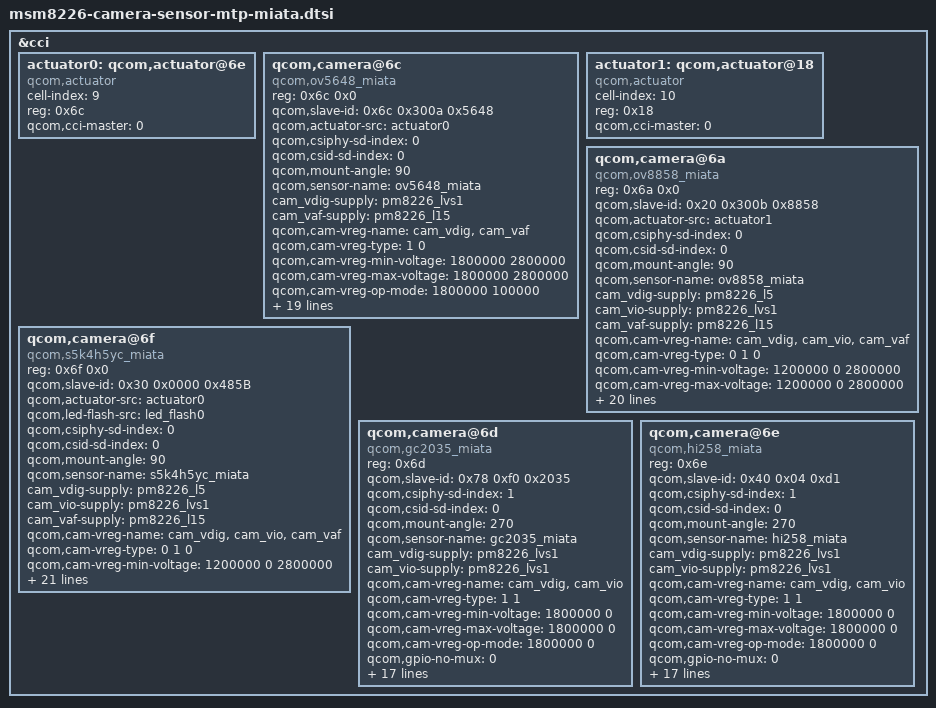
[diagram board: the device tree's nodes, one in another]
/*
 * Copyright (c) 2013, The Linux Foundation. All rights reserved.
 *
 * This program is free software; you can redistribute it and/or modify
 * it under the terms of the GNU General Public License version 2 and
 * only version 2 as published by the Free Software Foundation.
 *
 * This program is distributed in the hope that it will be useful,
 * but WITHOUT ANY WARRANTY; without even the implied warranty of
 * MERCHANTABILITY or FITNESS FOR A PARTICULAR PURPOSE.  See the
 * GNU General Public License for more details.
 *         Modify History For This Module
 * When           Who             What,Where,Why
 * --------------------------------------------------------------------------------------
 * 13/08/22      Hu Jin       Add driver for RoilTF's 1st main CAM
 * 13/10/22      Wang Penglei       Add driver for MIATA's 1st sub CAM GC2035
 * 13/10/25      Hu Jin       Add driver for MIATA's 1st main CAM ov5648
 * 13/10/29      Hu Jin       optimize
 * 13/11/26      Hu Jin       miata all main CAM -> 8M
 * 13/11/27      Hu Jin       fix 5M&8M issue
 * 13/12/11      Hu Jin       for i2c compatibility
 * 14/01/09      Hu Jin       Delete the old i2c
 * 14/01/19      Hu Jin       Camera can not be found on production
 * --------------------------------------------------------------------------------------
 */
// remove by shicuiping for we have not a camera flash start
/*&soc {

	led_flash0: qcom,camera-led-flash {
		cell-index = <0>;
		compatible = "qcom,camera-led-flash";
		qcom,flash-type = <1>;
		qcom,flash-source = <&pm8226_flash0 &pm8226_flash1>;
		qcom,torch-source = <&pm8226_torch>;
	};
};*/
// remove by shicuiping for we have not a camera flash stop

&cci {

	actuator0: qcom,actuator@6e {
		cell-index = <9>;/* [PLATFORM]-Mod by TCTNB.HJ, 2013/10/25*/
		reg = <0x6c>;
		compatible = "qcom,actuator";
		qcom,cci-master = <0>;
	};
/* [PLATFORM]-Mod-BEGIN by TCTNB.HJ, 2013/10/25*/
/*
	qcom,camera@6f {
		compatible = "qcom,ov8825";
		reg = <0x6f>;
		qcom,slave-id = <0x6c 0x300a 0x8825>;
		qcom,csiphy-sd-index = <0>;
		qcom,csid-sd-index = <0>;
		qcom,actuator-src = <&actuator0>;
		//qcom,led-flash-src = <&led_flash0>; // remove by shicuiping for we have not a camera flash
		qcom,mount-angle = <270>;
		qcom,sensor-name = "ov8825";
		cam_vdig-supply = <&pm8226_l5>;
		cam_vana-supply = <&pm8226_l19>;
		cam_vio-supply = <&pm8226_lvs1>;
		cam_vaf-supply = <&pm8226_l15>;
		qcom,cam-vreg-name = "cam_vdig", "cam_vio", "cam_vana",
							 "cam_vaf";
		qcom,cam-vreg-type = <0 1 0 0>;
		qcom,cam-vreg-min-voltage = <1200000 0 2850000 2800000>;
		qcom,cam-vreg-max-voltage = <1200000 0 2850000 2800000>;
		qcom,cam-vreg-op-mode = <200000 0 80000 100000>;
		qcom,gpio-no-mux = <0>;
		gpios = <&msmgpio 26 0>,
			<&msmgpio 37 0>,
			<&msmgpio 35 0>;
		qcom,gpio-reset = <1>;
		qcom,gpio-standby = <2>;
		qcom,gpio-req-tbl-num = <0 1 2>;
		qcom,gpio-req-tbl-flags = <1 0 0>;
		qcom,gpio-req-tbl-label = "CAMIF_MCLK",
			"CAM_RESET1",
			"CAM_STANDBY";
		qcom,csi-lane-assign = <0x4320>;
		qcom,csi-lane-mask = <0x1f>;
		qcom,sensor-position = <0>;
		qcom,sensor-mode = <1>;
		qcom,cci-master = <0>;
	};

	qcom,camera@6d {
		compatible = "qcom,ov9724";
		reg = <0x6d>;
		qcom,slave-id = <0x20 0x0 0x9724>;
		qcom,csiphy-sd-index = <1>;
		qcom,csid-sd-index = <1>;
		qcom,mount-angle = <270>;
		qcom,sensor-name = "ov9724";
		cam_vdig-supply = <&pm8226_l5>;
		cam_vana-supply = <&pm8226_l19>;
		cam_vio-supply = <&pm8226_lvs1>;
		qcom,cam-vreg-name = "cam_vdig", "cam_vio", "cam_vana";
		qcom,cam-vreg-type = <0 1 0>;
		qcom,cam-vreg-min-voltage = <1200000 0 2850000>;
		qcom,cam-vreg-max-voltage = <1200000 0 2850000>;
		qcom,cam-vreg-op-mode = <200000 0 80000>;
		qcom,gpio-no-mux = <0>;
		gpios = <&msmgpio 26 0>,
				<&msmgpio 28 0>,
				<&msmgpio 36 0>;
		qcom,gpio-reset = <1>;
		qcom,gpio-standby = <2>;
		qcom,gpio-req-tbl-num = <0 1 2>;
		qcom,gpio-req-tbl-flags = <1 0 0>;
		qcom,gpio-req-tbl-label = "CAMIF_MCLK",
				"CAM_RESET",
				"CAM_STANDBY";
		qcom,gpio-set-tbl-num = <1 1>;
		qcom,gpio-set-tbl-flags = <0 2>;
		qcom,gpio-set-tbl-delay = <1000 4000>;
		qcom,csi-lane-assign = <0x4320>;
		qcom,csi-lane-mask = <0x3>;
		qcom,sensor-position = <1>;
		qcom,sensor-mode = <1>;
		qcom,cci-master = <0>;
		status = "ok";
	};
*/
/* [PLATFORM]-Mod-END by TCTNB.HJ, 2013/10/25*/
/* [PLATFORM]-Mod-BEGIN by TCTNB.HJ, 2013/08/22, 1st main CAM dev (5M)*/
	qcom,camera@6c {
		compatible = "qcom,ov5648_miata";
		reg = <0x6c 0x0>;
		qcom,slave-id = <0x6c 0x300a 0x5648>;
		qcom,actuator-src = <&actuator0>;
		//qcom,led-flash-src = <&led_flash0>; // remove by shicuiping for we have not a camera flash
		qcom,csiphy-sd-index = <0>;
		qcom,csid-sd-index = <0>;
		qcom,mount-angle = <90>;
		qcom,sensor-name = "ov5648_miata";
		cam_vdig-supply = <&pm8226_lvs1>;
		cam_vaf-supply = <&pm8226_l15>;
		qcom,cam-vreg-name = "cam_vdig", "cam_vaf";
		qcom,cam-vreg-type = <1 0>;
		qcom,cam-vreg-min-voltage = <1800000 2800000>;
		qcom,cam-vreg-max-voltage = <1800000 2800000>;
		qcom,cam-vreg-op-mode = <1800000 100000>;
		qcom,gpio-no-mux = <0>;
		gpios = <&msmgpio 26 0>,
				<&msmgpio 37 0>,
				<&msmgpio 36 0>,
				<&msmgpio 31 0>,
				<&msmgpio 23 0>;
		qcom,gpio-reset = <1>;
		qcom,gpio-standby = <2>;
	       qcom,gpio-vana = <3>;
	       qcom,gpio-af-pwdm = <4>;
		qcom,gpio-req-tbl-num = <0 1 2 3 4>;
		qcom,gpio-req-tbl-flags = <1 0 0 0 0>;
		qcom,gpio-req-tbl-label = "CAMIF_MCLK",
				"CAM_RESET",
				"CAM_STANDBY",
				"CAM_VANA",
				"CAM_AF_PWDM";
		qcom,gpio-set-tbl-flags = <0 2>;
		qcom,gpio-set-tbl-delay = <1000 4000>;
		qcom,csi-lane-assign = <0x4320>;
		qcom,csi-lane-mask = <0x3>;
		qcom,sensor-position = <0>;
		qcom,sensor-mode = <0>;
		qcom,cci-master = <0>;
	};
/* [PLATFORM]-Mod-END by TCTNB.HJ, 2013/08/22 */

/* [PLATFORM]-Mod-BEGIN by TCTNB.HJ, 2013/11/26, 1st main CAM dev (8M)*/
	actuator1: qcom,actuator@18 {
		cell-index = <10>;
		reg = <0x18>;
		compatible = "qcom,actuator";
		qcom,cci-master = <0>;
	};
/* [PLATFORM]-Add-BEGIN by TCTNB.WPL, 2013/12/26, 2nd main CAM dev, refer to bug569849*/
    qcom,camera@6a {
        compatible = "qcom,ov8858_miata";
        reg = <0x6a 0x0>;
        qcom,slave-id = <0x20 0x300b 0x8858>;
        qcom,actuator-src = <&actuator1>;
        //qcom,led-flash-src = <&led_flash0>; // remove by shicuiping for we have not a camera flash
        qcom,csiphy-sd-index = <0>;
        qcom,csid-sd-index = <0>;
        qcom,mount-angle = <90>;
        qcom,sensor-name = "ov8858_miata";
        cam_vdig-supply = <&pm8226_l5>;
        cam_vio-supply = <&pm8226_lvs1>;
        cam_vaf-supply = <&pm8226_l15>;
        qcom,cam-vreg-name = "cam_vdig","cam_vio", "cam_vaf";
        qcom,cam-vreg-type = <0 1 0>;

        qcom,cam-vreg-min-voltage = <1200000 0 2800000>;
        qcom,cam-vreg-max-voltage = <1200000 0 2800000>;
        qcom,cam-vreg-op-mode = <200000 0 100000>;

        qcom,gpio-no-mux = <0>;
        gpios = <&msmgpio 26 0>,
                <&msmgpio 37 0>,
                <&msmgpio 36 0>,
                <&msmgpio 31 0>,
                <&msmgpio 23 0>;
        qcom,gpio-reset = <1>;
        qcom,gpio-standby = <2>;
           qcom,gpio-vana = <3>;
           qcom,gpio-af-pwdm = <4>;
        qcom,gpio-req-tbl-num = <0 1 2 3 4>;
        qcom,gpio-req-tbl-flags = <1 0 0 0 0>;
        qcom,gpio-req-tbl-label = "CAMIF_MCLK",
                "CAM_RESET",
                "CAM_STANDBY",
                "CAM_VANA",
                "CAM_AF_PWDM";
        qcom,gpio-set-tbl-flags = <0 2>;
        qcom,gpio-set-tbl-delay = <1000 4000>;
        qcom,csi-lane-assign = <0x4320>;
        qcom,csi-lane-mask = <0x3>;
        qcom,sensor-position = <0>;
        qcom,sensor-mode = <0>;
        qcom,cci-master = <0>;
    };
/* [PLATFORM]-Add-END by TCTNB.WPL, 2013/12/26 */

    qcom,camera@6f {
        compatible = "qcom,s5k4h5yc_miata";
        reg = <0x6f 0x0>;
        qcom,slave-id = <0x30 0x0000 0x485B>;
        qcom,actuator-src = <&actuator0>;
        qcom,led-flash-src = <&led_flash0>;
        qcom,csiphy-sd-index = <0>;
        qcom,csid-sd-index = <0>;
        qcom,mount-angle = <90>;
        qcom,sensor-name = "s5k4h5yc_miata";
        cam_vdig-supply = <&pm8226_l5>;
        cam_vio-supply = <&pm8226_lvs1>;
        cam_vaf-supply = <&pm8226_l15>;
        qcom,cam-vreg-name = "cam_vdig","cam_vio", "cam_vaf";
        qcom,cam-vreg-type = <0 1 0>;
        qcom,cam-vreg-min-voltage = <1200000 0 2800000>;
        qcom,cam-vreg-max-voltage = <1200000 0 2800000>;
        qcom,cam-vreg-op-mode = <200000 0 100000>;
        qcom,gpio-no-mux = <0>;
        gpios = <&msmgpio 26 0>,
                <&msmgpio 37 0>,
                <&msmgpio 36 0>,
                <&msmgpio 31 0>,
                <&msmgpio 23 0>;
        qcom,gpio-reset = <1>;
        qcom,gpio-standby = <2>;
           qcom,gpio-vana = <3>;
           qcom,gpio-af-pwdm = <4>;
        qcom,gpio-req-tbl-num = <0 1 2 3 4>;
        qcom,gpio-req-tbl-flags = <1 0 0 0 0>;
        qcom,gpio-req-tbl-label = "CAMIF_MCLK",
                "CAM_RESET",
                "CAM_STANDBY",
                "CAM_VANA",
                "CAM_AF_PWDM";
        qcom,gpio-set-tbl-flags = <0 2>;
        qcom,gpio-set-tbl-delay = <1000 4000>;
        qcom,csi-lane-assign = <0x4320>;
        qcom,csi-lane-mask = <0x3>;
        qcom,sensor-position = <0>;
        qcom,sensor-mode = <0>;
        qcom,cci-master = <0>;
    };
/* [PLATFORM]-Mod-END by TCTNB.HJ, 2013/11/26 */

/* [PLATFORM]-Add-BEGIN by TCTNB.WPL, 2013/10/22, 1st sub CAM dev, refer to bug514151*/
	qcom,camera@6d {
	compatible = "qcom,gc2035_miata";
	reg = <0x6d>;
	qcom,slave-id = <0x78 0xf0 0x2035>;
	qcom,csiphy-sd-index = <1>;
	qcom,csid-sd-index = <0>;
	qcom,mount-angle = <270>;
	qcom,sensor-name = "gc2035_miata";
	cam_vdig-supply = <&pm8226_lvs1>;
	cam_vio-supply = <&pm8226_lvs1>;
	qcom,cam-vreg-name = "cam_vdig", "cam_vio";
	qcom,cam-vreg-type = <1 1>;
	qcom,cam-vreg-min-voltage = <1800000 0>;
	qcom,cam-vreg-max-voltage = <1800000 0>;
	qcom,cam-vreg-op-mode = <1800000 0>;
	qcom,gpio-no-mux = <0>;
	gpios = <&msmgpio 26 0>,
			<&msmgpio 28 0>,
			<&msmgpio 35 0>,
			<&msmgpio 31 0>;
	qcom,gpio-reset = <1>;
	qcom,gpio-standby = <2>;
       qcom,gpio-vana = <3>;
	qcom,gpio-req-tbl-num = <0 1 2 3>;
	qcom,gpio-req-tbl-flags = <1 0 0 0>;
	qcom,gpio-req-tbl-label = "CAMIF_MCLK",
			"CAM_RESET",
			"CAM_STANDBY",
			"CAM_VANA";
	qcom,gpio-set-tbl-num = <1 1>;
	qcom,gpio-set-tbl-flags = <0 2>;
	qcom,gpio-set-tbl-delay = <1000 4000>;
	qcom,csi-lane-assign = <0x4320>;
	qcom,csi-lane-mask = <0x3>;
	qcom,sensor-position = <1>;
	qcom,sensor-mode = <1>;
	qcom,cci-master = <0>;
    status = "ok";
	};
	
/* [PLATFORM]-Add-END by TCTNB.WPL, 2013/10/22 */

/* [PLATFORM]-Add-BEGIN by TCTNB.WPL, 2013/12/11, add for miata 2nd sub camera, refer to bug569866 */
	qcom,camera@6e {
	compatible = "qcom,hi258_miata";
	reg = <0x6e>;
	qcom,slave-id = <0x40 0x04 0xd1>;
	qcom,csiphy-sd-index = <1>;
	qcom,csid-sd-index = <0>;
	qcom,mount-angle = <270>;
	qcom,sensor-name = "hi258_miata";
	cam_vdig-supply = <&pm8226_lvs1>;
	cam_vio-supply = <&pm8226_lvs1>;
	qcom,cam-vreg-name = "cam_vdig", "cam_vio";
	qcom,cam-vreg-type = <1 1>;
	qcom,cam-vreg-min-voltage = <1800000 0>;
	qcom,cam-vreg-max-voltage = <1800000 0>;
	qcom,cam-vreg-op-mode = <1800000 0>;
	qcom,gpio-no-mux = <0>;
	gpios = <&msmgpio 26 0>,
			<&msmgpio 28 0>,
			<&msmgpio 35 0>,
			<&msmgpio 31 0>;
	qcom,gpio-reset = <1>;
	qcom,gpio-standby = <2>;
       qcom,gpio-vana = <3>;
	qcom,gpio-req-tbl-num = <0 1 2 3>;
	qcom,gpio-req-tbl-flags = <1 0 0 0>;
	qcom,gpio-req-tbl-label = "CAMIF_MCLK",
			"CAM_RESET",
			"CAM_STANDBY",
			"CAM_VANA";
	qcom,gpio-set-tbl-num = <1 1>;
	qcom,gpio-set-tbl-flags = <0 2>;
	qcom,gpio-set-tbl-delay = <1000 4000>;
	qcom,csi-lane-assign = <0x4320>;
	qcom,csi-lane-mask = <0x3>;
	qcom,sensor-position = <1>;
	qcom,sensor-mode = <1>;
	qcom,cci-master = <0>;
    status = "ok";
	};
/* [PLATFORM]-Add-END by TCTNB.WPL, 2013/12/11 */
};
